# WS63 register map
File version: 1.0
CPU: other r0p0, little endian, MPU, FPU, 3 interrupt priority bits
Registers are 32-bit, read-write, reset 0x0 unless marked. A register's access mark holds for its fields unless they carry their own. Offsets are from the block's base; [hi:lo] are bit positions; {n}, {i} and the like mark numbered series.

## UART0 — UART0 - Universal Asynchronous Receiver/Transmitter
Base 0x44010000
Same registers: UART1 0x44011000, UART2 0x44012000
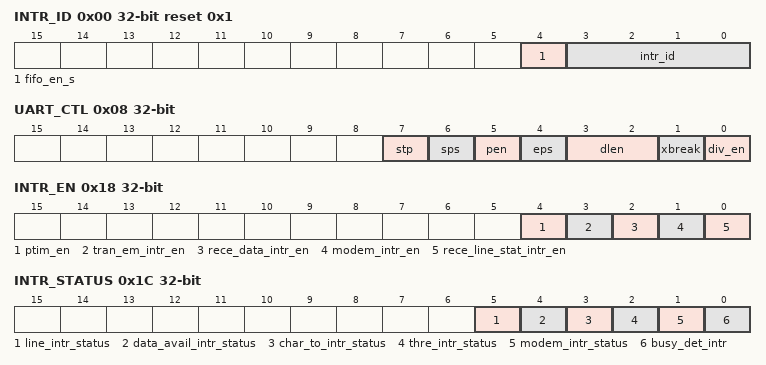
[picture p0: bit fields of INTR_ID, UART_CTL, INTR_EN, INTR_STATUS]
0x00 INTR_ID ro reset 0x1 — Interrupt ID register
  [4] fifo_en_s — FIFO enable status: 0=FIFO disabled; 1=FIFO enabled
  [3:0] intr_id — Interrupt ID: 0x0=modem status; 0x1=no interrupt; 0x2=THR empty; 0x4=rx data; 0x6=rx line status; 0x7=busy; 0xC=char timeout
0x04 DATA
  [7:0] data — Write: TX data; Read: RX data
0x08 UART_CTL — UART control register
  [7] stp — Stop bits: 0=1bit; 1=1.5/2bit
    0=Stop1 (1 stop bit); 1=Stop1_5_or_2 (1.5 (5-bit data) or 2 stop bits)
  [6] sps — Sticky parity: 0=disabled; 1=enabled
  [5] pen — Parity enable: 0=disabled; 1=enabled
    0=Disabled (No parity); 1=Enabled (Parity enabled)
  [4] eps — Parity select: 0=odd; 1=even
    0=Odd (Odd parity); 1=Even parity
  [3:2] dlen — Data length: 00=5bit; 01=6bit; 10=7bit; 11=8bit
    {v}=Bits{v+5} ({v+5}-bit data) (v=0..3)
  [1] xbreak — Break control: 0=normal; 1=force TX to space
  [0] div_en — Divider enable: 0=div accessible when not busy; 1=div accessible anytime
0x0C DIV_H range 0..255 — Baud rate divider high byte (write only when UART_CTL[div_en]=1 or UART not busy)
  [7:0] div_h — Divider integer high 8 bits
0x10 DIV_L range 0..255 — Baud rate divider low byte (write only when UART_CTL[div_en]=1 or UART not busy)
  [7:0] div_l — Divider integer low 8 bits
0x14 DIV_FRA — Baud rate divider fractional part
  [5:0] div_fra — Divider fractional part (divided by 2^6)
0x18 INTR_EN — Interrupt enable register
  [4] ptim_en — Programmable THRE interrupt mode enable
  [3] tran_em_intr_en — TX empty interrupt enable
  [2] rece_data_intr_en — RX data available interrupt enable
  [1] modem_intr_en — Modem status interrupt enable
  [0] rece_line_stat_intr_en — RX line status interrupt enable
0x1C INTR_STATUS ro — Interrupt status register
  [5] line_intr_status — RX line interrupt status
  [4] data_avail_intr_status — RX data available interrupt status
  [3] char_to_intr_status — Character timeout interrupt status
  [2] thre_intr_status — THR empty interrupt status
  [1] modem_intr_status — Modem interrupt status
  [0] busy_det_intr — Busy detect interrupt status
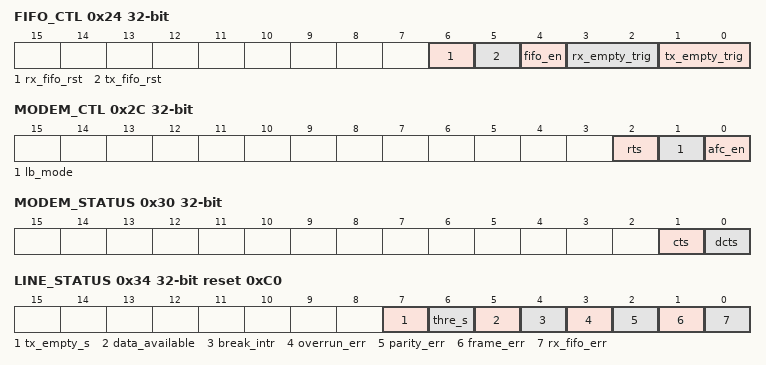
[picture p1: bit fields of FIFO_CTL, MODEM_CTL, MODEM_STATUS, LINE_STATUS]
0x24 FIFO_CTL wo — FIFO control register
  [6] rx_fifo_rst — RX FIFO reset: 0=no reset; 1=reset
  [5] tx_fifo_rst — TX FIFO reset: 0=no reset; 1=reset
  [4] fifo_en — FIFO enable
  [3:2] rx_empty_trig — RX trigger: 00=1char; 01=1/4; 10=1/2; 11=2below full
    0=Char1 (1 character in FIFO); 1=Quarter (FIFO 1/4 full); 2=Half (FIFO 1/2 full); 3=Less2 (2 below full)
  [1:0] tx_empty_trig — TX empty trigger: 00=empty; 01=2chars; 10=1/4; 11=1/2
    0=Empty (FIFO empty); 1=Chars2 (2 characters remaining); 2=Quarter (FIFO 1/4 full); 3=Half (FIFO 1/2 full)
0x28 FAR — FIFO access mode enable register
  [0] far — FIFO access mode: 0=disabled; 1=enabled
0x2C MODEM_CTL — Modem control register
  [2] rts — RTS software control
  [1] lb_mode — Loopback mode: 0=disabled; 1=enabled
  [0] afc_en — Auto flow control enable
0x30 MODEM_STATUS ro
  [1] cts — CTS signal state
  [0] dcts — CTS change indicator
0x34 LINE_STATUS ro reset 0xC0
  [7] tx_empty_s — Transmitter empty flag
  [6] thre_s — THR empty flag
  [5] data_available — Data available in RX FIFO/RBR
  [4] break_intr — Break interrupt
  [3] overrun_err — Overrun error
  [2] parity_err — Parity error
  [1] frame_err — Framing error
  [0] rx_fifo_err — RX FIFO error status
0x38 UART_GP_REG — UART general purpose register
  [7:0] uart_gp_reg — General purpose storage
0x3C TX_FIFO_READ ro
  [7:0] tx_fifo_read — TX FIFO top data
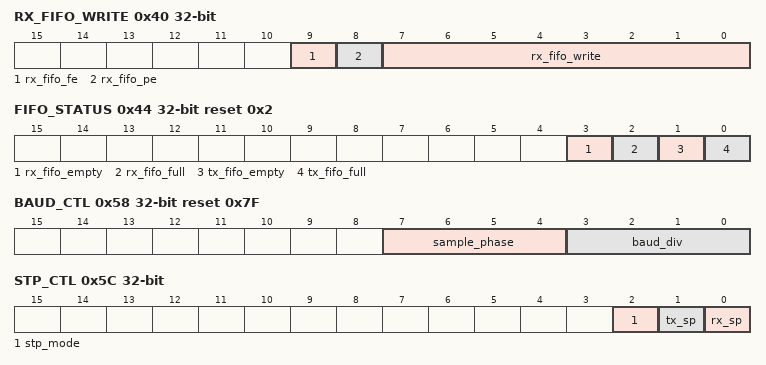
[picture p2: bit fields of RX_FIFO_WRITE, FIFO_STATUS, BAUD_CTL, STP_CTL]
0x40 RX_FIFO_WRITE
  [9] rx_fifo_fe wo — RX FIFO framing error
  [8] rx_fifo_pe wo — RX FIFO parity error
  [7:0] rx_fifo_write — Write: push data to RX FIFO; Read: rx_fifo_level[6:0]
0x44 FIFO_STATUS ro reset 0x2
  [3] rx_fifo_empty — RX FIFO empty flag
  [2] rx_fifo_full — RX FIFO full flag
  [1] tx_fifo_empty — TX FIFO empty flag
  [0] tx_fifo_full — TX FIFO full flag
0x48 TX_FIFO_CNT ro — TX FIFO data counter
  [6:0] tx_fifo_level — TX FIFO data count
0x4C RX_FIFO_CNT ro — RX FIFO data counter
0x50 HALT_TX — TX halt register
  [0] halt_tx — TX halt: 0=disabled; 1=enabled
0x54 DMA_SW_ACK — DMA software acknowledge register
  [0] dma_sw_ack wo — DMA software acknowledge (write-clear)
0x58 BAUD_CTL reset 0x7F — Baud rate control register
  [7:4] sample_phase — RX sample phase
  [3:0] baud_div — Baud rate oversampling: 0x7=8x; 0xF=16x
    7=Div8 (8x oversampling); 15=Div16 (16x oversampling)
0x5C STP_CTL — Stop bit control register
  [2] stp_mode — Stop bit control mode: 0=UART_CTL stp; 1=STP_CTL
  [1] tx_sp — TX stop bits when stp_mode=1
  [0] rx_sp — RX stop bits when stp_mode=1
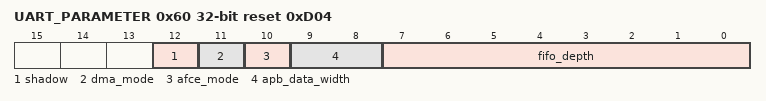
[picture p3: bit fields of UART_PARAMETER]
0x60 UART_PARAMETER ro reset 0xD04
  [12] shadow — Shadow feature enable
  [11] dma_mode — DMA mode: 0=DMA_EXTRA disabled; 1=enabled
  [10] afce_mode — AFCE mode: 0=disabled; 1=enabled
  [9:8] apb_data_width — APB data width: 0x1=16bit
  [7:0] fifo_depth — FIFO depth: 0x4=64
